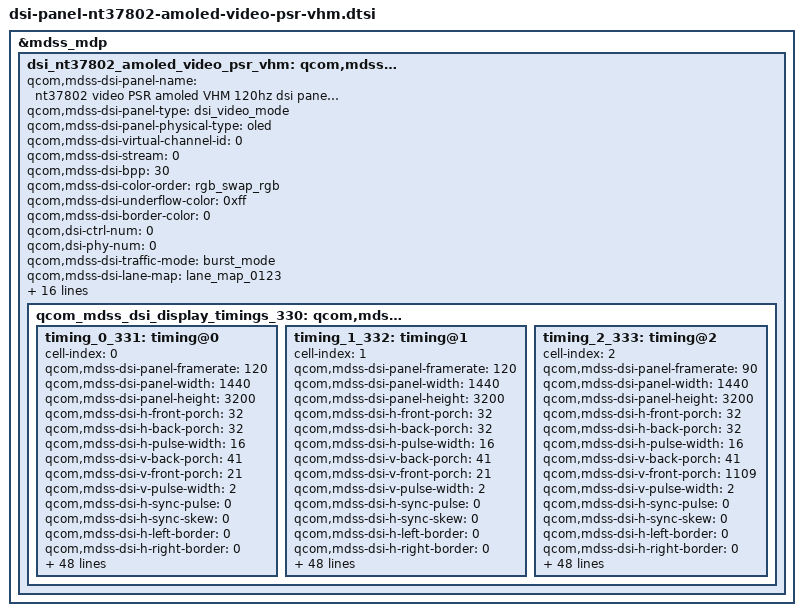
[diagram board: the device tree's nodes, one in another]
// SPDX-License-Identifier: BSD-3-Clause
/*
 * Copyright (c) Qualcomm Technologies, Inc. and/or its subsidiaries.
 */

&mdss_mdp {
	dsi_nt37802_amoled_video_psr_vhm: qcom,mdss_dsi_nt37802_amoled_video_psr_vhm {
		qcom,mdss-dsi-panel-name = "nt37802 video PSR amoled VHM 120hz dsi panel with DSC";
		qcom,mdss-dsi-panel-type = "dsi_video_mode";
		qcom,mdss-dsi-panel-physical-type = "oled";
		qcom,mdss-dsi-virtual-channel-id = <0>;
		qcom,mdss-dsi-stream = <0>;
		qcom,mdss-dsi-bpp = <30>;
		qcom,mdss-dsi-color-order = "rgb_swap_rgb";
		qcom,mdss-dsi-underflow-color = <0xff>;
		qcom,mdss-dsi-border-color = <0>;
		qcom,dsi-ctrl-num = <0>;
		qcom,dsi-phy-num = <0>;
		qcom,mdss-dsi-traffic-mode = "burst_mode";
		qcom,mdss-dsi-lane-map = "lane_map_0123";
		qcom,mdss-dsi-bllp-eof-power-mode;
		qcom,mdss-dsi-bllp-power-mode;
		qcom,mdss-dsi-lane-0-state;
		qcom,mdss-dsi-lane-1-state;
		qcom,mdss-dsi-lane-2-state;
		qcom,mdss-dsi-lane-3-state;
		qcom,mdss-dsi-dma-trigger = "trigger_sw";
		qcom,mdss-dsi-mdp-trigger = "none";
		qcom,mdss-dsi-reset-sequence =<1 1>, <0 1>, <1 10>;
		qcom,mdss-pan-physical-width-dimension = <701>;
		qcom,mdss-pan-physical-height-dimension = <1558>;
		qcom,mdss-dsi-tx-eot-append;
		qcom,mdss-dsi-lp11-init;
		qcom,mdss-dsi-panel-dimming-enabled;
		qcom,bl-update-flag = "delay_until_first_frame";
		qcom,mdss-disable-cesta-hw-sleep;

		qcom_mdss_dsi_display_timings_330: qcom,mdss-dsi-display-timings {
			timing_0_331: timing@0 {
				cell-index = <0>;
				qcom,mdss-dsi-panel-framerate = <120>;
				qcom,mdss-dsi-panel-width = <1440>;
				qcom,mdss-dsi-panel-height = <3200>;
				qcom,mdss-dsi-h-front-porch = <32>;
				qcom,mdss-dsi-h-back-porch = <32>;
				qcom,mdss-dsi-h-pulse-width = <16>;
				qcom,mdss-dsi-v-back-porch = <41>;
				qcom,mdss-dsi-v-front-porch = <21>;
				qcom,mdss-dsi-v-pulse-width = <2>;
				qcom,mdss-dsi-h-sync-pulse = <0>;
				qcom,mdss-dsi-h-sync-skew = <0>;
				qcom,mdss-dsi-h-left-border = <0>;
				qcom,mdss-dsi-h-right-border = <0>;
				qcom,mdss-dsi-v-top-border = <0>;
				qcom,mdss-dsi-v-bottom-border = <0>;

				qcom,mdss-dsi-video-mode;
				qcom,mdss-dsi-on-command = [
					// 1440x3200
					39 00 00 40 00 00 06 F0 55 AA 52 08 01
					15 00 00 40 00 00 02 6F 06
					15 00 00 40 00 00 02 C4 01
					39 00 00 40 00 00 06 F0 55 AA 52 08 04
					15 00 00 40 00 00 02 C0 20
					39 00 00 40 00 00 06 F0 55 AA 52 08 00
					15 00 00 40 00 00 02 6F 35
					15 00 00 00 00 00 02 C0 23
					39 00 00 40 00 00 06 F0 55 AA 52 08 06
					39 00 00 40 00 00 06 B2 25 24 36 37 37
					39 00 00 40 00 00 06 B8 21 20 36 37 37
					39 00 00 40 00 00 05 2A 00 00 05 9F
					39 00 00 40 00 00 05 2B 00 00 0C 7F
					39 00 00 40 00 00 03 90 03 43
					39 00 00 40 00 00 13 91 AB A8 00 14 C2
					   00 02 68 02 2E 00 0A 05 0E 03 D1 10
					   F0
					15 00 00 40 00 00 02 2F 00
					15 00 00 40 00 00 02 35 00
					39 00 00 40 00 00 03 51 0F FF
					15 00 00 40 00 00 02 6F 04
					39 00 00 40 00 00 03 51 0F FF
					15 00 00 00 00 00 02 53 20
					39 00 00 40 00 00 06 F0 55 AA 52 08 08
					39 00 00 40 00 00 17 C1 8E FF EE FF FF
					   EE FF FF EE FF FF EE FF FF EE FF FF
					   FF 7F FF 0E FF
					15 00 00 40 00 00 02 6F 20
					39 00 00 40 00 00 04 C1 FF FF FF
					15 00 00 40 00 00 02 6F 23
					39 00 00 00 00 00 15 C1 0E FF EE FF FF
					   EE FF FF EE FF FF EE FF FF EE FF FF
					   FF 7F FF

					// internal VGL
					39 01 00 02 00 00 06 F0 55 AA 52 08 00
					15 01 00 02 00 00 02 6F 10
					39 01 00 02 00 00 11 B5 00 71 71 71 71
					   71 00 00 18 29 00 00 00 18 29 00
					15 01 00 02 00 00 02 6F 11
					15 01 00 02 00 00 02 BE 40
					39 01 00 02 00 00 06 F0 55 AA 52 08 01
					15 01 00 02 00 00 02 6F 04
					15 01 00 02 00 00 02 B2 30

					// qsync supported modify
					15 00 00 40 00 00 02 6F 74
					39 00 00 40 00 00 11 BA 00 01 02 03 04
					   05 07 09 0B 77 EF 00 03 77 0B 00
					15 00 00 40 00 00 02 6F 84
					39 00 00 40 00 00 11 BA 00 01 02 03 04
					   05 07 09 0B 77 EF 00 03 77 0B 00
					15 00 00 40 00 00 02 6F 94
					39 00 00 40 00 00 11 BA 00 00 00 00 00
					   00 00 00 00 00 00 00 00 00 00 00
					15 00 00 40 00 00 02 6F A4
					39 00 00 40 00 00 11 BA 01 01 01 01 00
					   01 01 01 00 01 01 01 00 00 00 01
					15 00 00 40 00 00 02 6F B4
					39 00 00 40 00 00 05 BA 02 55 95 3E
					15 00 00 40 00 00 02 6F B8
					39 00 00 40 00 00 09 BA 00 00 00 00
					   00 10 00 00
					15 00 00 40 00 00 02 6F C0
					39 00 00 40 00 00 09 BA 00 00 00 00 00
					   10 00 00
					15 00 00 40 00 00 02 6F 6E
					39 00 00 40 00 00 03 D1 03 48
					// ap-spr
					39 00 00 40 00 00 13 91 AB A8 00 14 C2
					   00 02 68 02 2E 00 0A 05 0E 03 D1 10
					   F0
					39 00 00 40 00 00 06 F0 55 AA 52 08 03
					15 00 00 40 00 00 02 6F 09
					39 00 00 40 00 00 07 DE 10 34 25 30 14
					   25
					39 00 00 40 00 00 06 F0 55 AA 52 08 07
					39 00 00 40 00 00 06 F0 55 AA 52 08 07
					39 00 00 40 00 00 06 B0 84 40 00 00 00
					// round corner off
					39 00 00 40 00 00 06 F0 55 AA 52 08 07
					15 00 00 00 00 00 02 C0 86
					// vsync synchronization
					39 00 00 40 00 00 06 F0 55 AA 52 08 00
					15 00 00 40 00 00 02 6F 03
					15 00 00 40 00 00 02 BE 4F
					15 00 00 40 00 00 02 6F 0B
					15 00 00 00 00 00 02 BE 02
					// 120HZ
					15 00 00 40 00 00 02 2F 30
					15 00 00 00 00 00 02 6D 00
					// fix TE
					15 00 00 40 00 00 02 6F 14
					15 00 00 40 00 00 02 35 66
					15 00 00 40 00 00 02 6F 04
					15 00 00 40 00 00 02 35 00
					15 00 00 00 00 00 02 5A 00

					39 00 00 00 00 00 04 8C 00 00 11
					// cv switch
					39 00 00 40 00 00 06 F0 55 AA 52 08 00
					39 00 00 40 00 00 02 6F 1B
					39 00 00 40 00 00 02 C0 81
					39 00 00 40 00 00 04 2F 32 05 30
					39 00 00 40 00 00 05 3B 00 2B 00 15
					39 00 00 40 00 00 02 6F 04
					39 00 00 40 00 00 05 3B 00 2B 04 55
					39 00 00 40 00 00 06 F0 55 AA 52 08 00
					39 00 00 40 00 00 02 6F 24
					39 00 00 00 00 00 07 C9 0C C0 11 00 0C
					   C0
					39 00 00 00 00 00 02 71 01

					39 00 00 00 00 00 06 F0 55 AA 52 08 00
					15 00 00 00 00 00 02 6F 0D
					15 00 00 00 00 00 02 D8 40

					// panel esync
					39 00 00 00 00 00 06 F0 55 AA 52 08 03
					39 00 00 00 00 00 02 6F 06
					39 00 00 00 00 00 02 BA 01

					// close te
					// 39 00 00 00 00 00 02 34 00

					// ESD Err pin indicate ram status
					39 00 00 00 00 00 06 F0 55 AA 52 08 00
					39 00 00 00 00 00 03 BE 47 45
					15 00 00 00 00 00 02 6F 05
					15 00 00 00 00 00 02 BE 28
					15 00 00 00 00 00 02 6F 19
					39 00 00 00 00 00 05 BE 10 18 00 01

					// STILL Init
					39 01 00 00 00 00 06 F0 55 AA 52 08 00
					39 01 00 00 00 00 03 BE 5F 45
					15 01 00 00 00 00 02 6F 14
					39 01 00 00 00 00 0D 35 6C 6A 7D 6C 6A
					   7D 6C 6A 7D 6C 6A 7D
					39 01 00 00 00 00 06 F0 55 AA 52 08 00
					15 01 00 00 00 00 02 6F 04
					15 01 00 00 00 00 02 BA 00
					39 01 00 00 00 00 04 2F 32 05 00
					15 01 00 00 00 00 02 6F 26
					39 01 00 00 00 00 08 44 00 1A 00 1A 1A
					   0C C0
					15 01 00 00 00 00 02 6F 02
					15 01 00 00 00 00 02 35 18
					15 01 00 00 00 00 02 6F 42
					39 01 00 00 00 00 03 44 00 1A
					15 01 00 00 00 00 02 6F 64
					39 01 00 00 00 00 03 44 00 1A
					15 01 00 00 00 00 02 6F 0C
					15 01 00 00 00 00 02 35 00
					15 01 00 00 00 00 02 6D 08

					// EM
					39 00 00 00 00 00 06 F0 55 AA 52 08 00
					39 00 00 00 00 00 03 BE 5F 45
					39 00 00 00 00 00 02 6F 14
					39 00 00 00 00 00 0D 35 77 77 7D 77 77
					   7D 77 77 7D 77 77 7D
					39 00 00 00 00 00 06 F0 55 AA 52 08 00
					39 00 00 00 00 00 02 6F 04
					39 00 00 00 00 00 02 BA 00
					39 00 00 00 00 00 04 2F 32 05 00
					39 00 00 00 00 00 02 6F 26
					39 00 00 00 00 00 08 44 00 1A 00 1A 1A
					   0C C0
					39 00 00 00 00 00 02 6F 02
					39 00 00 00 00 00 02 35 18
					39 00 00 00 00 00 02 6F 42
					39 00 00 00 00 00 03 44 00 1A
					39 00 00 00 00 00 02 6F 64
					39 00 00 00 00 00 03 44 00 1A
					39 00 00 00 00 00 02 6F 0C
					39 00 00 00 00 00 02 35 00
					39 00 00 00 00 00 02 6D 08

					39 00 00 00 00 00 04 2F 32 05 30
					39 00 00 00 00 00 06 F0 55 AA 52 08 00
					39 00 00 00 00 00 02 6F 35
					39 00 00 00 00 00 02 B1 10

					39 00 00 00 00 00 06 F0 55 AA 52 08 00
					39 00 00 00 00 00 02 6F 6E
					39 00 00 00 00 00 03 D1 03 C9

					// VHM TE
					39 00 00 02 00 00 06 F0 55 AA 52 08 00
					15 00 00 02 00 00 02 BE 5F

					39 01 00 00 00 00 06 F0 55 AA 52 08 00
					39 01 00 00 00 00 03 BE 47 45

					15 01 00 00 00 00 02 6F 14
					39 01 00 00 00 00 0D 35 6A 77 7D 6A 77
					   7D 6A 77 7D 6A 77 7D

					15 01 00 00 00 00 02 6F 26
					39 01 00 00 00 00 03 44 00 22
					15 01 00 00 00 00 02 6F 28
					39 01 00 00 00 00 03 44 00 22
					15 01 00 00 00 00 02 6F 42
					39 01 00 00 00 00 03 44 00 22
					15 01 00 00 00 00 02 6F 64
					39 01 00 00 00 00 03 44 00 22

					15 01 00 00 00 00 02 6F 2A
					15 01 00 00 00 00 02 44 1A

					15 01 00 00 00 00 02 6F 2B
					39 01 00 00 00 00 03 44 0C C0

					15 01 00 00 00 00 02 6F 02
					15 01 00 00 00 00 02 35 18

					15 01 00 00 00 00 02 6F 0C
					15 01 00 00 00 00 02 35 00

					15 01 00 00 00 00 02 6D 08

					39 01 00 00 00 00 04 2F 32 05 30

					39 01 00 00 00 00 06 F0 55 AA 52 08 00
					15 01 00 00 00 00 02 6F 04
					15 01 00 00 00 00 02 BA 00

					39 01 00 00 00 00 06 F0 55 AA 52 08 00
					15 01 00 00 00 00 02 6F 35
					15 01 00 00 00 00 02 B1 10

					39 01 00 00 00 00 06 F0 55 AA 52 08 00
					15 01 00 00 00 00 02 6F DD
					15 01 00 00 00 00 02 BA 80

					39 01 00 00 00 00 06 F0 55 AA 52 08 08
					15 01 00 00 00 00 02 6F 02
					15 01 00 00 00 00 02 E0 81

					// Sleep Out
					05 00 00 00 78 00 01 11
					// Display On
					05 00 00 00 00 00 01 29
				];

				qcom,mdss-dsi-off-command = [
					// VinitN1=-4
					39 00 00 40 00 00 06 F0 55 AA 52 08 01
					15 00 00 40 00 00 02 6F 09
					39 00 00 40 00 00 1E BA AA AA AA AA AA
					   2A A0 A0 A0 A0 A0 A0 A0 A0 A0 A0 A0
					   A0 A0 A0 A0 A0 A0 A0 A0 A0 A0 A0 A0
					15 00 00 40 00 00 02 6F 27
					39 00 00 40 00 00 1E BA AA AA AA AA AA
					   2A A0 A0 A0 A0 A0 A0 A0 A0 A0 A0 A0
					   A0 A0 A0 A0 A0 A0 A0 A0 A0 A0 A0 A0
					15 00 00 40 00 00 02 53 00
					39 00 00 40 00 00 03 51 00 00
					05 00 00 00 1E 00 01 28
					05 00 00 00 78 00 01 10
				];

				qcom,mdss-dsi-sticky_still_en-command = [
					39 01 00 00 00 00 14 A9 01 00 18 00 00
					   01 01 00 35 0C 0C 18 02 00 D1 6E 6F
					   03 C8
				];

				qcom,mdss-dsi-sticky_still_disable-command = [
					39 01 00 00 00 00 14 A9 01 00 18 00 00
					   00 01 00 35 0C 0C 00 02 00 D1 6E 6F
					   03 C9
				];

				qcom,mdss-dsi-freq-step-pattern1-command = [
					39 01 00 00 00 00 06 F0 55 AA 52 08 00
				];

				qcom,mdss-dsi-freq-step-pattern2-command = [
					39 01 00 00 00 00 06 F0 55 AA 52 08 01
				];

				qcom,mdss-dsi-freq-step-pattern3-command = [
					39 01 00 00 00 00 06 F0 55 AA 52 08 01
				];

				qcom,mdss-dsi-em-pulse-switch-command = [
					39 01 00 00 00 00 06 F0 55 AA 52 08 00
				];

				qcom,mdss-dsi-qsync-freq-pattren-needs-selfrefresh =
					<1 1>;
				qcom,mdss-dsi-qsync-freq-step-sequence-interval =
					<0 120000 2>, <0 30000 1>, <1 120000 1>;
				qcom,mdss-dsi-qsync-freq-step-sequence =
					<30000 1>, <10000 1>,
					<10000 1>,
					<10000 1>;
				qcom,mdss-dsi-on-command-state = "dsi_lp_mode";
				qcom,mdss-dsi-off-command-state = "dsi_hs_mode";
				qcom,mdss-dsi-sticky_still_en-command-state = "dsi_hs_mode";
				qcom,mdss-dsi-sticky_still_disable-command-state = "dsi_hs_mode";
				qcom,mdss-dsi-freq-step-pattern1-command-state = "dsi_hs_mode";
				qcom,mdss-dsi-freq-step-pattern2-command-state = "dsi_hs_mode";
				qcom,mdss-dsi-freq-step-pattern3-command-state = "dsi_hs_mode";
				qcom,mdss-dsi-em-pulse-switch-command-state = "dsi_hs_mode";

				qcom,compression-mode = "dsc";
				qcom,mdss-dsc-version = <0x12>;
				qcom,mdss-dsc-scr-version = <0x0>;
				qcom,mdss-dsc-slice-height = <20>;
				qcom,mdss-dsc-slice-width = <720>;
				qcom,mdss-dsc-slice-per-pkt = <2>;
				qcom,mdss-dsc-bit-per-component = <10>;
				qcom,mdss-dsc-bit-per-pixel = <8>;
				qcom,mdss-dsc-block-prediction-enable;
			};

			timing_1_332: timing@1 {
				cell-index = <1>;
				qcom,mdss-dsi-panel-framerate = <120>;
				qcom,mdss-dsi-panel-width = <1440>;
				qcom,mdss-dsi-panel-height = <3200>;
				qcom,mdss-dsi-h-front-porch = <32>;
				qcom,mdss-dsi-h-back-porch = <32>;
				qcom,mdss-dsi-h-pulse-width = <16>;
				qcom,mdss-dsi-v-back-porch = <41>;
				qcom,mdss-dsi-v-front-porch = <21>;
				qcom,mdss-dsi-v-pulse-width = <2>;
				qcom,mdss-dsi-h-sync-pulse = <0>;
				qcom,mdss-dsi-h-sync-skew = <0>;
				qcom,mdss-dsi-h-left-border = <0>;
				qcom,mdss-dsi-h-right-border = <0>;
				qcom,mdss-dsi-v-top-border = <0>;
				qcom,mdss-dsi-v-bottom-border = <0>;

				qcom,mdss-dsi-video-mode;
				qcom,mdss-dsi-on-command = [
					// 1440x3200
					39 00 00 40 00 00 06 F0 55 AA 52 08 01
					15 00 00 40 00 00 02 6F 06
					15 00 00 40 00 00 02 C4 01
					39 00 00 40 00 00 06 F0 55 AA 52 08 04
					15 00 00 40 00 00 02 C0 20
					39 00 00 40 00 00 06 F0 55 AA 52 08 00
					15 00 00 40 00 00 02 6F 35
					15 00 00 00 00 00 02 C0 23
					39 00 00 40 00 00 06 F0 55 AA 52 08 06
					39 00 00 40 00 00 06 B2 25 24 36 37 37
					39 00 00 40 00 00 06 B8 21 20 36 37 37
					39 00 00 40 00 00 05 2A 00 00 05 9F
					39 00 00 40 00 00 05 2B 00 00 0C 7F
					39 00 00 40 00 00 03 90 03 43
					39 00 00 40 00 00 13 91 AB A8 00 14 C2
					   00 02 68 02 2E 00 0A 05 0E 03 D1 10
					   F0
					15 00 00 40 00 00 02 2F 00
					15 00 00 40 00 00 02 35 00
					39 00 00 40 00 00 03 51 0F FF
					15 00 00 40 00 00 02 6F 04
					39 00 00 40 00 00 03 51 0F FF
					15 00 00 00 00 00 02 53 20
					39 00 00 40 00 00 06 F0 55 AA 52 08 08
					39 00 00 40 00 00 17 C1 8E FF EE FF FF
					   EE FF FF EE FF FF EE FF FF EE FF FF
					   FF 7F FF 0E FF
					15 00 00 40 00 00 02 6F 20
					39 00 00 40 00 00 04 C1 FF FF FF
					15 00 00 40 00 00 02 6F 23
					39 00 00 00 00 00 15 C1 0E FF EE FF FF
					   EE FF FF EE FF FF EE FF FF EE FF FF
					   FF 7F FF

					// internal VGL
					39 01 00 02 00 00 06 F0 55 AA 52 08 00
					15 01 00 02 00 00 02 6F 10
					39 01 00 02 00 00 11 B5 00 71 71 71 71
					   71 00 00 18 29 00 00 00 18 29 00
					15 01 00 02 00 00 02 6F 11
					15 01 00 02 00 00 02 BE 40
					39 01 00 02 00 00 06 F0 55 AA 52 08 01
					15 01 00 02 00 00 02 6F 04
					15 01 00 02 00 00 02 B2 30

					// qsync supported modify
					15 00 00 40 00 00 02 6F 74
					39 00 00 40 00 00 11 BA 00 01 02 03 04
					   05 07 09 0B 77 EF 00 03 77 0B 00
					15 00 00 40 00 00 02 6F 84
					39 00 00 40 00 00 11 BA 00 01 02 03 04
					   05 07 09 0B 77 EF 00 03 77 0B 00
					15 00 00 40 00 00 02 6F 94
					39 00 00 40 00 00 11 BA 00 00 00 00 00
					   00 00 00 00 00 00 00 00 00 00 00
					15 00 00 40 00 00 02 6F A4
					39 00 00 40 00 00 11 BA 01 01 01 01 00
					   01 01 01 00 01 01 01 00 00 00 01
					15 00 00 40 00 00 02 6F B4
					39 00 00 40 00 00 05 BA 02 55 95 3E
					15 00 00 40 00 00 02 6F B8
					39 00 00 40 00 00 09 BA 00 00 00 00
					   00 10 00 00
					15 00 00 40 00 00 02 6F C0
					39 00 00 40 00 00 09 BA 00 00 00 00 00
					   10 00 00
					15 00 00 40 00 00 02 6F 6E
					39 00 00 40 00 00 03 D1 03 48
					// ap-spr
					39 00 00 40 00 00 13 91 AB A8 00 14 C2
					   00 02 68 02 2E 00 0A 05 0E 03 D1 10
					   F0
					39 00 00 40 00 00 06 F0 55 AA 52 08 03
					15 00 00 40 00 00 02 6F 09
					39 00 00 40 00 00 07 DE 10 34 25 30 14
					   25
					39 00 00 40 00 00 06 F0 55 AA 52 08 07
					39 00 00 40 00 00 06 F0 55 AA 52 08 07
					39 00 00 40 00 00 06 B0 84 40 00 00 00
					// round corner off
					39 00 00 40 00 00 06 F0 55 AA 52 08 07
					15 00 00 00 00 00 02 C0 86
					// vsync synchronization
					39 00 00 40 00 00 06 F0 55 AA 52 08 00
					15 00 00 40 00 00 02 6F 03
					15 00 00 40 00 00 02 BE 4F
					15 00 00 40 00 00 02 6F 0B
					15 00 00 00 00 00 02 BE 02
					// 120HZ
					15 00 00 40 00 00 02 2F 30
					15 00 00 00 00 00 02 6D 00
					// fix TE
					15 00 00 40 00 00 02 6F 14
					15 00 00 40 00 00 02 35 66
					15 00 00 40 00 00 02 6F 04
					15 00 00 40 00 00 02 35 00
					15 00 00 00 00 00 02 5A 00

					39 00 00 00 00 00 04 8C 00 00 11
					// cv switch
					39 00 00 40 00 00 06 F0 55 AA 52 08 00
					39 00 00 40 00 00 02 6F 1B
					39 00 00 40 00 00 02 C0 81
					39 00 00 40 00 00 04 2F 32 05 30
					39 00 00 40 00 00 05 3B 00 2B 00 15
					39 00 00 40 00 00 02 6F 04
					39 00 00 40 00 00 05 3B 00 2B 04 55
					39 00 00 40 00 00 06 F0 55 AA 52 08 00
					39 00 00 40 00 00 02 6F 24
					39 00 00 00 00 00 07 C9 0C C0 11 00 0C
					   C0
					39 00 00 00 00 00 02 71 01

					39 00 00 00 00 00 06 F0 55 AA 52 08 00
					15 00 00 00 00 00 02 6F 0D
					15 00 00 00 00 00 02 D8 40

					// panel esync
					39 00 00 00 00 00 06 F0 55 AA 52 08 03
					39 00 00 00 00 00 02 6F 06
					39 00 00 00 00 00 02 BA 01

					// close te
					// 39 00 00 00 00 00 02 34 00

					// ESD Err pin indicate ram status
					39 00 00 00 00 00 06 F0 55 AA 52 08 00
					39 00 00 00 00 00 03 BE 47 45
					15 00 00 00 00 00 02 6F 05
					15 00 00 00 00 00 02 BE 28
					15 00 00 00 00 00 02 6F 19
					39 00 00 00 00 00 05 BE 10 18 00 01

					// STILL Init
					39 01 00 00 00 00 06 F0 55 AA 52 08 00
					39 01 00 00 00 00 03 BE 5F 45
					15 01 00 00 00 00 02 6F 14
					39 01 00 00 00 00 0D 35 6C 6A 7D 6C 6A
					   7D 6C 6A 7D 6C 6A 7D
					39 01 00 00 00 00 06 F0 55 AA 52 08 00
					15 01 00 00 00 00 02 6F 04
					15 01 00 00 00 00 02 BA 00
					39 01 00 00 00 00 04 2F 32 05 00
					15 01 00 00 00 00 02 6F 26
					39 01 00 00 00 00 08 44 00 1A 00 1A 1A
					   0C C0
					15 01 00 00 00 00 02 6F 02
					15 01 00 00 00 00 02 35 18
					15 01 00 00 00 00 02 6F 42
					39 01 00 00 00 00 03 44 00 1A
					15 01 00 00 00 00 02 6F 64
					39 01 00 00 00 00 03 44 00 1A
					15 01 00 00 00 00 02 6F 0C
					15 01 00 00 00 00 02 35 00
					15 01 00 00 00 00 02 6D 08

					// EM
					39 00 00 00 00 00 06 F0 55 AA 52 08 00
					39 00 00 00 00 00 03 BE 5F 45
					39 00 00 00 00 00 02 6F 14
					39 00 00 00 00 00 0D 35 77 77 7D 77 77
					   7D 77 77 7D 77 77 7D
					39 00 00 00 00 00 06 F0 55 AA 52 08 00
					39 00 00 00 00 00 02 6F 04
					39 00 00 00 00 00 02 BA 00
					39 00 00 00 00 00 04 2F 32 05 00
					39 00 00 00 00 00 02 6F 26
					39 00 00 00 00 00 08 44 00 1A 00 1A 1A
					   0C C0
					39 00 00 00 00 00 02 6F 02
					39 00 00 00 00 00 02 35 18
					39 00 00 00 00 00 02 6F 42
					39 00 00 00 00 00 03 44 00 1A
					39 00 00 00 00 00 02 6F 64
					39 00 00 00 00 00 03 44 00 1A
					39 00 00 00 00 00 02 6F 0C
					39 00 00 00 00 00 02 35 00
					39 00 00 00 00 00 02 6D 08

					39 00 00 00 00 00 04 2F 32 05 30
					39 00 00 00 00 00 06 F0 55 AA 52 08 00
					39 00 00 00 00 00 02 6F 35
					39 00 00 00 00 00 02 B1 10

					39 00 00 00 00 00 06 F0 55 AA 52 08 00
					39 00 00 00 00 00 02 6F 6E
					39 00 00 00 00 00 03 D1 03 C9

					// VHM TE
					39 00 00 02 00 00 06 F0 55 AA 52 08 00
					15 00 00 02 00 00 02 BE 5F

					39 01 00 00 00 00 06 F0 55 AA 52 08 00
					39 01 00 00 00 00 03 BE 47 45

					15 01 00 00 00 00 02 6F 14
					39 01 00 00 00 00 0D 35 6A 77 7D 6A 77
					   7D 6A 77 7D 6A 77 7D

					15 01 00 00 00 00 02 6F 26
					39 01 00 00 00 00 03 44 00 22
					15 01 00 00 00 00 02 6F 28
					39 01 00 00 00 00 03 44 00 22
					15 01 00 00 00 00 02 6F 42
					39 01 00 00 00 00 03 44 00 22
					15 01 00 00 00 00 02 6F 64
					39 01 00 00 00 00 03 44 00 22

					15 01 00 00 00 00 02 6F 2A
					15 01 00 00 00 00 02 44 1A

					15 01 00 00 00 00 02 6F 2B
					39 01 00 00 00 00 03 44 0C C0

					15 01 00 00 00 00 02 6F 02
					15 01 00 00 00 00 02 35 18

					15 01 00 00 00 00 02 6F 0C
					15 01 00 00 00 00 02 35 00

					15 01 00 00 00 00 02 6D 08

					39 01 00 00 00 00 04 2F 32 05 30

					39 01 00 00 00 00 06 F0 55 AA 52 08 00
					15 01 00 00 00 00 02 6F 04
					15 01 00 00 00 00 02 BA 00

					39 01 00 00 00 00 06 F0 55 AA 52 08 00
					15 01 00 00 00 00 02 6F 35
					15 01 00 00 00 00 02 B1 10

					39 01 00 00 00 00 06 F0 55 AA 52 08 00
					15 01 00 00 00 00 02 6F DD
					15 01 00 00 00 00 02 BA 80

					39 01 00 00 00 00 06 F0 55 AA 52 08 08
					15 01 00 00 00 00 02 6F 02
					15 01 00 00 00 00 02 E0 81

					// Sleep Out
					05 00 00 00 78 00 01 11
					// Display On
					05 00 00 00 00 00 01 29
				];

				qcom,mdss-dsi-off-command = [
					// VinitN1=-4
					39 00 00 40 00 00 06 F0 55 AA 52 08 01
					15 00 00 40 00 00 02 6F 09
					39 00 00 40 00 00 1E BA AA AA AA AA AA
					   2A A0 A0 A0 A0 A0 A0 A0 A0 A0 A0 A0
					   A0 A0 A0 A0 A0 A0 A0 A0 A0 A0 A0 A0
					15 00 00 40 00 00 02 6F 27
					39 00 00 40 00 00 1E BA AA AA AA AA AA
					   2A A0 A0 A0 A0 A0 A0 A0 A0 A0 A0 A0
					   A0 A0 A0 A0 A0 A0 A0 A0 A0 A0 A0 A0
					15 00 00 40 00 00 02 53 00
					39 00 00 40 00 00 03 51 00 00
					05 00 00 00 1E 00 01 28
					05 00 00 00 78 00 01 10
				];

				qcom,mdss-dsi-sticky_still_en-command = [
					39 01 00 00 00 00 14 A9 01 00 18 00 00
					   01 01 00 35 0C 0C 18 02 00 D1 6E 6F
					   03 C8
				];

				qcom,mdss-dsi-sticky_still_disable-command = [
					39 01 00 00 00 00 14 A9 01 00 18 00 00
					   00 01 00 35 0C 0C 00 02 00 D1 6E 6F
					   03 C9
				];

				qcom,mdss-dsi-freq-step-pattern1-command = [
					39 01 00 00 00 00 06 F0 55 AA 52 08 00
				];

				qcom,mdss-dsi-freq-step-pattern2-command = [
					39 01 00 00 00 00 06 F0 55 AA 52 08 01
				];

				qcom,mdss-dsi-freq-step-pattern3-command = [
					39 01 00 00 00 00 06 F0 55 AA 52 08 01
				];

				qcom,mdss-dsi-em-pulse-switch-command = [
					39 01 00 00 00 00 06 F0 55 AA 52 08 01
				];

				qcom,mdss-dsi-qsync-freq-pattren-needs-selfrefresh =
					<1 1>;
				qcom,mdss-dsi-qsync-freq-step-sequence-interval =
					<0 120000 2>, <0 30000 1>, <1 120000 1>;
				qcom,mdss-dsi-qsync-freq-step-sequence =
					<30000 1>, <10000 1>,
					<10000 1>,
					<10000 1>;
				qcom,mdss-dsi-on-command-state = "dsi_lp_mode";
				qcom,mdss-dsi-off-command-state = "dsi_hs_mode";
				qcom,mdss-dsi-sticky_still_en-command-state = "dsi_hs_mode";
				qcom,mdss-dsi-sticky_still_disable-command-state = "dsi_hs_mode";
				qcom,mdss-dsi-freq-step-pattern1-command-state = "dsi_hs_mode";
				qcom,mdss-dsi-freq-step-pattern2-command-state = "dsi_hs_mode";
				qcom,mdss-dsi-freq-step-pattern3-command-state = "dsi_hs_mode";
				qcom,mdss-dsi-em-pulse-switch-command-state = "dsi_hs_mode";

				qcom,compression-mode = "dsc";
				qcom,mdss-dsc-version = <0x12>;
				qcom,mdss-dsc-scr-version = <0x0>;
				qcom,mdss-dsc-slice-height = <20>;
				qcom,mdss-dsc-slice-width = <720>;
				qcom,mdss-dsc-slice-per-pkt = <2>;
				qcom,mdss-dsc-bit-per-component = <10>;
				qcom,mdss-dsc-bit-per-pixel = <8>;
				qcom,mdss-dsc-block-prediction-enable;
			};

			timing_2_333: timing@2 {
				cell-index = <2>;
				qcom,mdss-dsi-panel-framerate = <90>;
				qcom,mdss-dsi-panel-width = <1440>;
				qcom,mdss-dsi-panel-height = <3200>;
				qcom,mdss-dsi-h-front-porch = <32>;
				qcom,mdss-dsi-h-back-porch = <32>;
				qcom,mdss-dsi-h-pulse-width = <16>;
				qcom,mdss-dsi-v-back-porch = <41>;
				qcom,mdss-dsi-v-front-porch = <1109>;
				qcom,mdss-dsi-v-pulse-width = <2>;
				qcom,mdss-dsi-h-sync-pulse = <0>;
				qcom,mdss-dsi-h-sync-skew = <0>;
				qcom,mdss-dsi-h-left-border = <0>;
				qcom,mdss-dsi-h-right-border = <0>;
				qcom,mdss-dsi-v-top-border = <0>;
				qcom,mdss-dsi-v-bottom-border = <0>;

				qcom,mdss-dsi-video-mode;
				qcom,mdss-dsi-on-command = [
					// 1440x3200
					39 00 00 40 00 00 06 F0 55 AA 52 08 01
					15 00 00 40 00 00 02 6F 06
					15 00 00 40 00 00 02 C4 01
					39 00 00 40 00 00 06 F0 55 AA 52 08 04
					15 00 00 40 00 00 02 C0 20
					39 00 00 40 00 00 06 F0 55 AA 52 08 00
					15 00 00 40 00 00 02 6F 35
					15 00 00 00 00 00 02 C0 23
					39 00 00 40 00 00 06 F0 55 AA 52 08 06
					39 00 00 40 00 00 06 B2 25 24 36 37 37
					39 00 00 40 00 00 06 B8 21 20 36 37 37
					39 00 00 40 00 00 05 2A 00 00 05 9F
					39 00 00 40 00 00 05 2B 00 00 0C 7F
					39 00 00 40 00 00 03 90 03 43
					39 00 00 40 00 00 13 91 AB A8 00 14 C2
					   00 02 68 02 2E 00 0A 05 0E 03 D1 10
					   F0
					15 00 00 40 00 00 02 2F 00
					15 00 00 40 00 00 02 35 00
					39 00 00 40 00 00 03 51 0F FF
					15 00 00 40 00 00 02 6F 04
					39 00 00 40 00 00 03 51 0F FF
					15 00 00 00 00 00 02 53 20
					39 00 00 40 00 00 06 F0 55 AA 52 08 08
					39 00 00 40 00 00 17 C1 8E FF EE FF FF
					   EE FF FF EE FF FF EE FF FF EE FF FF
					   FF 7F FF 0E FF
					15 00 00 40 00 00 02 6F 20
					39 00 00 40 00 00 04 C1 FF FF FF
					15 00 00 40 00 00 02 6F 23
					39 00 00 00 00 00 15 C1 0E FF EE FF FF
					   EE FF FF EE FF FF EE FF FF EE FF FF
					   FF 7F FF

					// internal VGL
					39 01 00 02 00 00 06 F0 55 AA 52 08 00
					15 01 00 02 00 00 02 6F 10
					39 01 00 02 00 00 11 B5 00 71 71 71 71
					   71 00 00 18 29 00 00 00 18 29 00
					15 01 00 02 00 00 02 6F 11
					15 01 00 02 00 00 02 BE 40
					39 01 00 02 00 00 06 F0 55 AA 52 08 01
					15 01 00 02 00 00 02 6F 04
					15 01 00 02 00 00 02 B2 30

					// qsync supported modify
					15 00 00 40 00 00 02 6F 74
					39 00 00 40 00 00 11 BA 00 01 02 03 04
					   05 07 09 0B 77 EF 00 03 77 0B 00
					15 00 00 40 00 00 02 6F 84
					39 00 00 40 00 00 11 BA 00 01 02 03 04
					   05 07 09 0B 77 EF 00 03 77 0B 00
					15 00 00 40 00 00 02 6F 94
					39 00 00 40 00 00 11 BA 00 00 00 00 00
					   00 00 00 00 00 00 00 00 00 00 00
					15 00 00 40 00 00 02 6F A4
					39 00 00 40 00 00 11 BA 01 01 01 01 00
					   01 01 01 00 01 01 01 00 00 00 01
					15 00 00 40 00 00 02 6F B4
					39 00 00 40 00 00 05 BA 02 55 95 3E
					15 00 00 40 00 00 02 6F B8
					39 00 00 40 00 00 09 BA 00 00 00 00
					   00 10 00 00
					15 00 00 40 00 00 02 6F C0
					39 00 00 40 00 00 09 BA 00 00 00 00 00
					   10 00 00
					15 00 00 40 00 00 02 6F 6E
					39 00 00 40 00 00 03 D1 03 48
					// ap-spr
					39 00 00 40 00 00 13 91 AB A8 00 14 C2
					   00 02 68 02 2E 00 0A 05 0E 03 D1 10
					   F0
					39 00 00 40 00 00 06 F0 55 AA 52 08 03
					15 00 00 40 00 00 02 6F 09
					39 00 00 40 00 00 07 DE 10 34 25 30 14
					   25
					39 00 00 40 00 00 06 F0 55 AA 52 08 07
					39 00 00 40 00 00 06 F0 55 AA 52 08 07
					39 00 00 40 00 00 06 B0 84 40 00 00 00
					// round corner off
					39 00 00 40 00 00 06 F0 55 AA 52 08 07
					15 00 00 00 00 00 02 C0 86
					// vsync synchronization
					39 00 00 40 00 00 06 F0 55 AA 52 08 00
					15 00 00 40 00 00 02 6F 03
					15 00 00 40 00 00 02 BE 4F
					15 00 00 40 00 00 02 6F 0B
					15 00 00 00 00 00 02 BE 02
					// 120HZ
					15 00 00 40 00 00 02 2F 30
					15 00 00 00 00 00 02 6D 00
					// fix TE
					15 00 00 40 00 00 02 6F 14
					15 00 00 40 00 00 02 35 66
					15 00 00 40 00 00 02 6F 04
					15 00 00 40 00 00 02 35 00
					15 00 00 00 00 00 02 5A 00

					39 00 00 00 00 00 04 8C 00 00 11
					// cv switch
					39 00 00 40 00 00 06 F0 55 AA 52 08 00
					39 00 00 40 00 00 02 6F 1B
					39 00 00 40 00 00 02 C0 81
					39 00 00 40 00 00 04 2F 32 05 30
					39 00 00 40 00 00 05 3B 00 2B 00 15
					39 00 00 40 00 00 02 6F 04
					39 00 00 40 00 00 05 3B 00 2B 04 55
					39 00 00 40 00 00 06 F0 55 AA 52 08 00
					39 00 00 40 00 00 02 6F 24
					39 00 00 00 00 00 07 C9 0C C0 11 00 0C
					   C0
					39 00 00 00 00 00 02 71 01

					39 00 00 00 00 00 06 F0 55 AA 52 08 00
					15 00 00 00 00 00 02 6F 0D
					15 00 00 00 00 00 02 D8 40

					// panel esync
					39 00 00 00 00 00 06 F0 55 AA 52 08 03
					39 00 00 00 00 00 02 6F 06
					39 00 00 00 00 00 02 BA 01

					// close te
					// 39 00 00 00 00 00 02 34 00

					// ESD Err pin indicate ram status
					39 00 00 00 00 00 06 F0 55 AA 52 08 00
					39 00 00 00 00 00 03 BE 47 45
					15 00 00 00 00 00 02 6F 05
					15 00 00 00 00 00 02 BE 28
					15 00 00 00 00 00 02 6F 19
					39 00 00 00 00 00 05 BE 10 18 00 01

					// STILL Init
					39 01 00 00 00 00 06 F0 55 AA 52 08 00
					39 01 00 00 00 00 03 BE 5F 45
					15 01 00 00 00 00 02 6F 14
					39 01 00 00 00 00 0D 35 6C 6A 7D 6C 6A
					   7D 6C 6A 7D 6C 6A 7D
					39 01 00 00 00 00 06 F0 55 AA 52 08 00
					15 01 00 00 00 00 02 6F 04
					15 01 00 00 00 00 02 BA 00
					39 01 00 00 00 00 04 2F 32 05 00
					15 01 00 00 00 00 02 6F 26
					39 01 00 00 00 00 08 44 00 1A 00 1A 1A
					   0C C0
					15 01 00 00 00 00 02 6F 02
					15 01 00 00 00 00 02 35 18
					15 01 00 00 00 00 02 6F 42
					39 01 00 00 00 00 03 44 00 1A
					15 01 00 00 00 00 02 6F 64
					39 01 00 00 00 00 03 44 00 1A
					15 01 00 00 00 00 02 6F 0C
					15 01 00 00 00 00 02 35 00
					15 01 00 00 00 00 02 6D 08

					// EM
					39 00 00 00 00 00 06 F0 55 AA 52 08 00
					39 00 00 00 00 00 03 BE 5F 45
					39 00 00 00 00 00 02 6F 14
					39 00 00 00 00 00 0D 35 77 77 7D 77 77
					   7D 77 77 7D 77 77 7D
					39 00 00 00 00 00 06 F0 55 AA 52 08 00
					39 00 00 00 00 00 02 6F 04
					39 00 00 00 00 00 02 BA 00
					39 00 00 00 00 00 04 2F 32 05 00
					39 00 00 00 00 00 02 6F 26
					39 00 00 00 00 00 08 44 00 1A 00 1A 1A
					   0C C0
					39 00 00 00 00 00 02 6F 02
					39 00 00 00 00 00 02 35 18
					39 00 00 00 00 00 02 6F 42
					39 00 00 00 00 00 03 44 00 1A
					39 00 00 00 00 00 02 6F 64
					39 00 00 00 00 00 03 44 00 1A
					39 00 00 00 00 00 02 6F 0C
					39 00 00 00 00 00 02 35 00
					39 00 00 00 00 00 02 6D 08

					39 00 00 00 00 00 04 2F 32 05 30
					39 00 00 00 00 00 06 F0 55 AA 52 08 00
					39 00 00 00 00 00 02 6F 35
					39 00 00 00 00 00 02 B1 10

					39 00 00 00 00 00 06 F0 55 AA 52 08 00
					39 00 00 00 00 00 02 6F 6E
					39 00 00 00 00 00 03 D1 03 C9

					// VHM TE
					39 00 00 02 00 00 06 F0 55 AA 52 08 00
					15 00 00 02 00 00 02 BE 5F

					39 01 00 00 00 00 06 F0 55 AA 52 08 00
					39 01 00 00 00 00 03 BE 47 45

					15 01 00 00 00 00 02 6F 14
					39 01 00 00 00 00 0D 35 6A 77 7D 6A 77
					   7D 6A 77 7D 6A 77 7D

					15 01 00 00 00 00 02 6F 26
					39 01 00 00 00 00 03 44 00 22
					15 01 00 00 00 00 02 6F 28
					39 01 00 00 00 00 03 44 00 22
					15 01 00 00 00 00 02 6F 42
					39 01 00 00 00 00 03 44 00 22
					15 01 00 00 00 00 02 6F 64
					39 01 00 00 00 00 03 44 00 22

					15 01 00 00 00 00 02 6F 2A
					15 01 00 00 00 00 02 44 1A

					15 01 00 00 00 00 02 6F 2B
					39 01 00 00 00 00 03 44 0C C0

					15 01 00 00 00 00 02 6F 02
					15 01 00 00 00 00 02 35 18

					15 01 00 00 00 00 02 6F 0C
					15 01 00 00 00 00 02 35 00

					15 01 00 00 00 00 02 6D 08

					39 01 00 00 00 00 04 2F 32 05 30

					39 01 00 00 00 00 06 F0 55 AA 52 08 00
					15 01 00 00 00 00 02 6F 04
					15 01 00 00 00 00 02 BA 00

					39 01 00 00 00 00 06 F0 55 AA 52 08 00
					15 01 00 00 00 00 02 6F 35
					15 01 00 00 00 00 02 B1 10

					39 01 00 00 00 00 06 F0 55 AA 52 08 00
					15 01 00 00 00 00 02 6F DD
					15 01 00 00 00 00 02 BA 80

					39 01 00 00 00 00 06 F0 55 AA 52 08 08
					15 01 00 00 00 00 02 6F 02
					15 01 00 00 00 00 02 E0 81

					// Sleep Out
					05 00 00 00 78 00 01 11
					// Display On
					05 00 00 00 00 00 01 29
				];

				qcom,mdss-dsi-off-command = [
					// VinitN1=-4
					39 00 00 40 00 00 06 F0 55 AA 52 08 01
					15 00 00 40 00 00 02 6F 09
					39 00 00 40 00 00 1E BA AA AA AA AA AA
					   2A A0 A0 A0 A0 A0 A0 A0 A0 A0 A0 A0
					   A0 A0 A0 A0 A0 A0 A0 A0 A0 A0 A0 A0
					15 00 00 40 00 00 02 6F 27
					39 00 00 40 00 00 1E BA AA AA AA AA AA
					   2A A0 A0 A0 A0 A0 A0 A0 A0 A0 A0 A0
					   A0 A0 A0 A0 A0 A0 A0 A0 A0 A0 A0 A0
					15 00 00 40 00 00 02 53 00
					39 00 00 40 00 00 03 51 00 00
					05 00 00 00 1E 00 01 28
					05 00 00 00 78 00 01 10
				];

				qcom,mdss-dsi-sticky_still_en-command = [
					39 01 00 00 00 00 14 A9 01 00 18 00 00
					   01 01 00 35 0C 0C 18 02 00 D1 6E 6F
					   03 C8
				];

				qcom,mdss-dsi-sticky_still_disable-command = [
					39 01 00 00 00 00 14 A9 01 00 18 00 00
					   00 01 00 35 0C 0C 00 02 00 D1 6E 6F
					   03 C9
				];

				qcom,mdss-dsi-freq-step-pattern1-command = [
					39 01 00 00 00 00 06 F0 55 AA 52 08 00
				];

				qcom,mdss-dsi-freq-step-pattern2-command = [
					39 01 00 00 00 00 06 F0 55 AA 52 08 01
				];

				qcom,mdss-dsi-freq-step-pattern3-command = [
					39 01 00 00 00 00 06 F0 55 AA 52 08 01
				];

				qcom,mdss-dsi-em-pulse-switch-command = [
					39 01 00 00 00 00 06 F0 55 AA 52 08 01
				];

				qcom,mdss-dsi-qsync-freq-pattren-needs-selfrefresh =
					<1 1>;
				qcom,mdss-dsi-qsync-freq-step-sequence-interval =
					<0 120000 2>, <0 30000 1>, <1 120000 1>;
				qcom,mdss-dsi-qsync-freq-step-sequence =
					<30000 1>, <10000 1>,
					<10000 1>,
					<10000 1>;
				qcom,mdss-dsi-on-command-state = "dsi_lp_mode";
				qcom,mdss-dsi-off-command-state = "dsi_hs_mode";
				qcom,mdss-dsi-sticky_still_en-command-state = "dsi_hs_mode";
				qcom,mdss-dsi-sticky_still_disable-command-state = "dsi_hs_mode";
				qcom,mdss-dsi-freq-step-pattern1-command-state = "dsi_hs_mode";
				qcom,mdss-dsi-freq-step-pattern2-command-state = "dsi_hs_mode";
				qcom,mdss-dsi-freq-step-pattern3-command-state = "dsi_hs_mode";
				qcom,mdss-dsi-em-pulse-switch-command-state = "dsi_hs_mode";

				qcom,compression-mode = "dsc";
				qcom,mdss-dsc-version = <0x12>;
				qcom,mdss-dsc-scr-version = <0x0>;
				qcom,mdss-dsc-slice-height = <20>;
				qcom,mdss-dsc-slice-width = <720>;
				qcom,mdss-dsc-slice-per-pkt = <2>;
				qcom,mdss-dsc-bit-per-component = <10>;
				qcom,mdss-dsc-bit-per-pixel = <8>;
				qcom,mdss-dsc-block-prediction-enable;
			};
		};
	};
};
